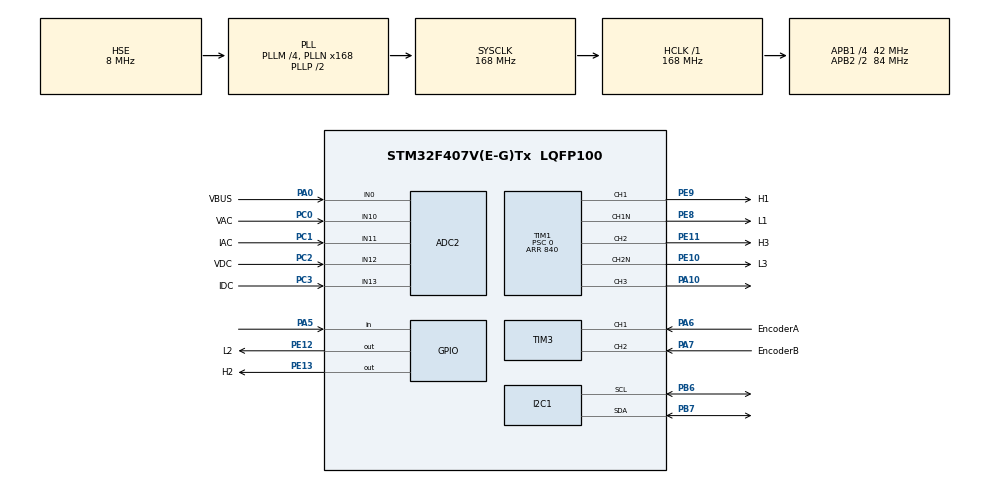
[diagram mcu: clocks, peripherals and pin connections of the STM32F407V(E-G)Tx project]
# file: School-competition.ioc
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ADC1.Channel-2\#ChannelRegularConversion=ADC_CHANNEL_VREFINT
ADC1.EOCSelection=ADC_EOC_SEQ_CONV
ADC1.ExternalTrigConv=ADC_EXTERNALTRIGCONV_T1_CC3
ADC1.Mode=__NULL
ADC1.NbrOfConversionFlag=1
ADC1.Rank-2\#ChannelRegularConversion=1
ADC1.SamplingTime-2\#ChannelRegularConversion=ADC_SAMPLETIME_56CYCLES
ADC1.master=1
ADC2.Channel-0\#ChannelRegularConversion=ADC_CHANNEL_10
ADC2.Channel-16\#ChannelRegularConversion=ADC_CHANNEL_11
ADC2.Channel-17\#ChannelRegularConversion=ADC_CHANNEL_12
ADC2.Channel-18\#ChannelRegularConversion=ADC_CHANNEL_13
ADC2.Channel-19\#ChannelRegularConversion=ADC_CHANNEL_0
ADC2.DMAContinuousRequests=ENABLE
ADC2.DiscontinuousConvMode=DISABLE
ADC2.EOCSelection=ADC_EOC_SEQ_CONV
ADC2.EnableAnalogWatchDog=false
ADC2.ExternalTrigConv=ADC_EXTERNALTRIGCONV_T1_CC3
ADC2.InjNumberOfConversion=0
ADC2.NbrOfConversion=5
ADC2.NbrOfConversionFlag=1
ADC2.Rank-0\#ChannelRegularConversion=1
ADC2.Rank-16\#ChannelRegularConversion=2
ADC2.Rank-17\#ChannelRegularConversion=3
ADC2.Rank-18\#ChannelRegularConversion=4
ADC2.Rank-19\#ChannelRegularConversion=5
ADC2.SamplingTime-0\#ChannelRegularConversion=ADC_SAMPLETIME_15CYCLES
ADC2.SamplingTime-16\#ChannelRegularConversion=ADC_SAMPLETIME_15CYCLES
ADC2.SamplingTime-17\#ChannelRegularConversion=ADC_SAMPLETIME_15CYCLES
ADC2.SamplingTime-18\#ChannelRegularConversion=ADC_SAMPLETIME_15CYCLES
ADC2.SamplingTime-19\#ChannelRegularConversion=ADC_SAMPLETIME_15CYCLES
Dma.ADC2.0.Direction=DMA_PERIPH_TO_MEMORY
Dma.ADC2.0.FIFOMode=DMA_FIFOMODE_DISABLE
Dma.ADC2.0.Instance=DMA2_Stream2
Dma.ADC2.0.MemDataAlignment=DMA_MDATAALIGN_HALFWORD
Dma.ADC2.0.MemInc=DMA_MINC_ENABLE
Dma.ADC2.0.Mode=DMA_CIRCULAR
Dma.ADC2.0.PeriphDataAlignment=DMA_PDATAALIGN_HALFWORD
Dma.ADC2.0.PeriphInc=DMA_PINC_DISABLE
Dma.ADC2.0.Priority=DMA_PRIORITY_LOW
Dma.Request0=ADC2
Mcu.Family=STM32F4
Mcu.Name=STM32F407V(E-G)Tx
Mcu.Package=LQFP100
NVIC.ADC_IRQn=true\:0\:0\:true\:false\:true\:true\:true\:true
NVIC.DMA2_Stream2_IRQn=true\:1\:0\:true\:false\:true\:false\:true\:true
NVIC.PriorityGroup=NVIC_PRIORITYGROUP_2
NVIC.TIM4_IRQn=true\:2\:0\:true\:false\:true\:true\:true\:true
PA0-WKUP.GPIO_Label=VBUS
PA0-WKUP.Signal=ADCx_IN0
PA10.Signal=S_TIM1_CH3
PA13.Mode=Serial_Wire
PA13.Signal=SYS_JTMS-SWDIO
PA14.Mode=Serial_Wire
PA14.Signal=SYS_JTCK-SWCLK
PA5.GPIO_PuPd=GPIO_PULLUP
PA5.Signal=GPIO_Input
PA6.GPIO_Label=EncoderA
PA6.GPIO_PuPd=GPIO_PULLUP
PA6.Signal=S_TIM3_CH1
PA7.GPIO_Label=EncoderB
PA7.GPIO_PuPd=GPIO_PULLUP
PA7.Signal=S_TIM3_CH2
PB6.GPIO_Pu=GPIO_NOPULL
PB6.Mode=I2C
PB6.Signal=I2C1_SCL
PB7.GPIO_Pu=GPIO_NOPULL
PB7.Mode=I2C
PB7.Signal=I2C1_SDA
PC0.GPIO_Label=VAC
PC0.Signal=ADCx_IN10
PC1.GPIO_Label=IAC
PC1.Signal=ADCx_IN11
PC2.GPIO_Label=VDC
PC2.Signal=ADCx_IN12
PC3.GPIO_Label=IDC
PC3.Signal=ADCx_IN13
PE10.GPIO_Label=L3
PE10.Mode=PWM Generation2 CH2 CH2N
PE10.Signal=TIM1_CH2N
PE11.GPIO_Label=H3
PE11.Signal=S_TIM1_CH2
PE12.GPIO_Label=L2
PE12.Signal=GPIO_Output
PE13.GPIO_Label=H2
PE13.Signal=GPIO_Output
PE8.GPIO_Label=L1
PE8.Mode=PWM Generation1 CH1 CH1N
PE8.Signal=TIM1_CH1N
PE9.GPIO_Label=H1
PE9.Signal=S_TIM1_CH1
PH0-OSC_IN.Mode=HSE-External-Oscillator
PH0-OSC_IN.Signal=RCC_OSC_IN
PH1-OSC_OUT.Mode=HSE-External-Oscillator
PH1-OSC_OUT.Signal=RCC_OSC_OUT
ProjectManager.HeapSize=0x200
ProjectManager.StackSize=0x400
ProjectManager.TargetToolchain=MDK-ARM V5.32
RCC.48MHZClocksFreq_Value=84000000
RCC.AHBFreq_Value=168000000
RCC.APB1CLKDivider=RCC_HCLK_DIV4
RCC.APB1Freq_Value=42000000
RCC.APB1TimFreq_Value=84000000
RCC.APB2CLKDivider=RCC_HCLK_DIV2
RCC.APB2Freq_Value=84000000
RCC.APB2TimFreq_Value=168000000
RCC.CortexFreq_Value=168000000
RCC.HCLKFreq_Value=168000000
RCC.HSE_VALUE=8000000
RCC.HSI_VALUE=16000000
RCC.LSE_VALUE=32768
RCC.PLLM=4
RCC.PLLN=168
RCC.PLLSourceVirtual=RCC_PLLSOURCE_HSE
RCC.SYSCLKFreq_VALUE=168000000
RCC.SYSCLKSource=RCC_SYSCLKSOURCE_PLLCLK
RCC.VCOOutputFreq_Value=336000000
SH.ADCx_IN0.0=ADC2_IN0,IN0
SH.ADCx_IN10.0=ADC2_IN10,IN10
SH.ADCx_IN11.0=ADC2_IN11,IN11
SH.ADCx_IN12.0=ADC2_IN12,IN12
SH.ADCx_IN13.0=ADC2_IN13,IN13
SH.S_TIM1_CH1.0=TIM1_CH1,PWM Generation1 CH1 CH1N
SH.S_TIM1_CH2.0=TIM1_CH2,PWM Generation2 CH2 CH2N
SH.S_TIM1_CH3.0=TIM1_CH3,PWM Generation3 CH3
SH.S_TIM3_CH1.0=TIM3_CH1,Encoder_Interface
SH.S_TIM3_CH2.0=TIM3_CH2,Encoder_Interface
TIM1.Channel-PWM\ Generation1\ CH1\ CH1N=TIM_CHANNEL_1
TIM1.Channel-PWM\ Generation2\ CH2\ CH2N=TIM_CHANNEL_2
TIM1.Channel-PWM\ Generation3\ CH3=TIM_CHANNEL_3
TIM1.CounterMode=TIM_COUNTERMODE_CENTERALIGNED2
TIM1.DeadTime=5
TIM1.Period=840
TIM1.Prescaler=0
TIM1.Pulse-PWM\ Generation1\ CH1\ CH1N=420
TIM1.Pulse-PWM\ Generation2\ CH2\ CH2N=420
TIM1.Pulse-PWM\ Generation3\ CH3=420
TIM1.RepetitionCounter=0
TIM1.TIM_MasterOutputTrigger=TIM_TRGO_OC4REF
TIM1.TIM_MasterSlaveMode=TIM_MASTERSLAVEMODE_DISABLE
TIM3.ClockDivision=TIM_CLOCKDIVISION_DIV1
TIM3.EncoderMode=TIM_ENCODERMODE_TI12
TIM3.IC1Prescaler=TIM_ICPSC_DIV1
TIM3.IC2Prescaler=TIM_ICPSC_DIV1
TIM4.AutoReloadPreload=TIM_AUTORELOAD_PRELOAD_ENABLE
TIM4.Period=10000
TIM4.Prescaler=84 -1
TIM4.TIM_MasterOutputTrigger=TIM_TRGO_UPDATE
VP_ADC1_Vref_Input.Mode=IN-Vrefint
VP_TIM4_VS_ClockSourceINT.Mode=Internal
board=custom

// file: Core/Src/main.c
/* USER CODE BEGIN Header */
/**
  ******************************************************************************
  * @file           : main.c
  * @brief          : Main program body
  ******************************************************************************
  * @attention
  *
  * Copyright (c) 2026 STMicroelectronics.
  * All rights reserved.
  *
  * This software is licensed under terms that can be found in the LICENSE file
  * in the root directory of this software component.
  * If no LICENSE file comes with this software, it is provided AS-IS.
  *
  ******************************************************************************
  */
/* USER CODE END Header */
#include "main.h"
#include "adc.h"
#include "dma.h"
#include "i2c.h"
#include "tim.h"
#include "gpio.h"

/* USER CODE BEGIN Includes */
#include "OLED_GFX.h"
#include <stdio.h>
/* USER CODE END Includes */

void SystemClock_Config(void);

int main(void)
{

  /* MCU Configuration--------------------------------------------------------*/

  /* Reset of all peripherals, Initializes the Flash interface and the Systick. */
  HAL_Init();

  /* Configure the system clock */
  SystemClock_Config();

  /* Initialize all configured peripherals */
  MX_GPIO_Init();
  MX_DMA_Init();
  MX_TIM1_Init();
  MX_ADC1_Init();
  MX_ADC2_Init();
  MX_I2C1_Init();
  MX_TIM3_Init();
  MX_TIM4_Init();
  /* USER CODE BEGIN 2 */

	OLED_GFX_Init();
  // __HAL_TIM_SET_COMPARE(&htim1, TIM_CHANNEL_1, 420);
  // HAL_TIM_PWM_Start(&htim1, TIM_CHANNEL_1);
  // HAL_TIMEx_PWMN_Start(&htim1, TIM_CHANNEL_1);
  // __HAL_TIM_MOE_ENABLE(&htim1);

	OLED_ShowString(0, 0, "hello!");
	OLED_GFX_Refresh();

  /* USER CODE END 2 */

  /* Infinite loop */
  while (1)
  {

  }
}

void SystemClock_Config(void)
{
  RCC_OscInitTypeDef RCC_OscInitStruct = {0};
  RCC_ClkInitTypeDef RCC_ClkInitStruct = {0};

  /** Configure the main internal regulator output voltage
  */
  __HAL_RCC_PWR_CLK_ENABLE();
  __HAL_PWR_VOLTAGESCALING_CONFIG(PWR_REGULATOR_VOLTAGE_SCALE1);

  /** Initializes the RCC Oscillators according to the specified parameters
  * in the RCC_OscInitTypeDef structure.
  */
  RCC_OscInitStruct.OscillatorType = RCC_OSCILLATORTYPE_HSE;
  RCC_OscInitStruct.HSEState = RCC_HSE_ON;
  RCC_OscInitStruct.PLL.PLLState = RCC_PLL_ON;
  RCC_OscInitStruct.PLL.PLLSource = RCC_PLLSOURCE_HSE;
  RCC_OscInitStruct.PLL.PLLM = 4;
  RCC_OscInitStruct.PLL.PLLN = 168;
  RCC_OscInitStruct.PLL.PLLP = RCC_PLLP_DIV2;
  RCC_OscInitStruct.PLL.PLLQ = 4;
  if (HAL_RCC_OscConfig(&RCC_OscInitStruct) != HAL_OK)
  {
    Error_Handler();
  }

  /** Initializes the CPU, AHB and APB buses clocks
  */
  RCC_ClkInitStruct.ClockType = RCC_CLOCKTYPE_HCLK|RCC_CLOCKTYPE_SYSCLK
                              |RCC_CLOCKTYPE_PCLK1|RCC_CLOCKTYPE_PCLK2;
  RCC_ClkInitStruct.SYSCLKSource = RCC_SYSCLKSOURCE_PLLCLK;
  RCC_ClkInitStruct.AHBCLKDivider = RCC_SYSCLK_DIV1;
  RCC_ClkInitStruct.APB1CLKDivider = RCC_HCLK_DIV4;
  RCC_ClkInitStruct.APB2CLKDivider = RCC_HCLK_DIV2;

  if (HAL_RCC_ClockConfig(&RCC_ClkInitStruct, FLASH_LATENCY_5) != HAL_OK)
  {
    Error_Handler();
  }
}

void Error_Handler(void)
{
  __disable_irq();
  while (1)
  {
  }
}
